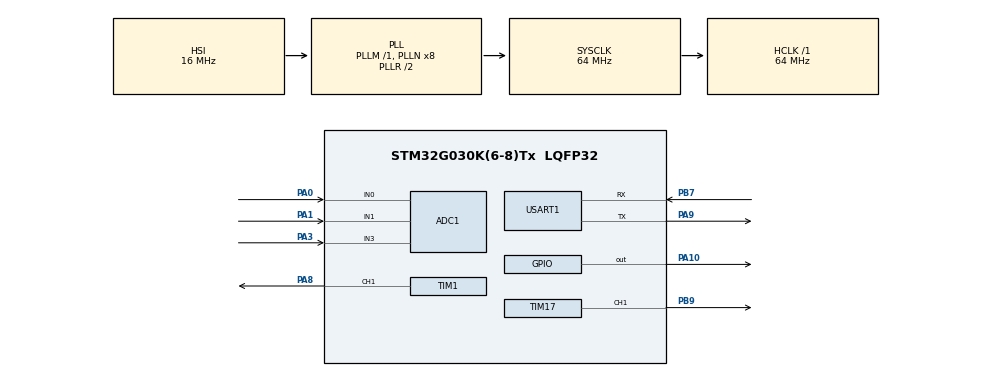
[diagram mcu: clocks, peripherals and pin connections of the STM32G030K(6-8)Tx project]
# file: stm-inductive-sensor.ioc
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ADC1.Channel-0\#ChannelRegularConversion=ADC_CHANNEL_1
ADC1.Channel-1\#ChannelRegularConversion=ADC_CHANNEL_3
ADC1.ClockPrescaler=ADC_CLOCK_ASYNC_DIV1
ADC1.ContinuousConvMode=ENABLE
ADC1.DMAContinuousRequests=DISABLE
ADC1.EOCSelection=ADC_EOC_SEQ_CONV
ADC1.ExternalTrigConv=ADC_SOFTWARE_START
ADC1.NbrOfConversion=2
ADC1.NbrOfConversionFlag=1
ADC1.Overrun=ADC_OVR_DATA_PRESERVED
ADC1.OversamplingMode=DISABLE
ADC1.Rank-0\#ChannelRegularConversion=1
ADC1.Rank-1\#ChannelRegularConversion=2
ADC1.SamplingTime-0\#ChannelRegularConversion=ADC_SAMPLINGTIME_COMMON_1
ADC1.SamplingTime-1\#ChannelRegularConversion=ADC_SAMPLINGTIME_COMMON_1
ADC1.SamplingTimeCommon1=ADC_SAMPLETIME_19CYCLES_5
ADC1.SamplingTimeCommon2=ADC_SAMPLETIME_39CYCLES_5
ADC1.SelectedChannel=ADC_CHANNEL_0|ADC_CHANNEL_1|ADC_CHANNEL_3
ADC1.Sequencer=FULLY_CONFIGURABLE
ADC1.TriggerFrequencyMode=ADC_TRIGGER_FREQ_HIGH
ADC1.master=1
Dma.ADC1.0.Direction=DMA_PERIPH_TO_MEMORY
Dma.ADC1.0.EventEnable=DISABLE
Dma.ADC1.0.Instance=DMA1_Channel1
Dma.ADC1.0.MemDataAlignment=DMA_MDATAALIGN_HALFWORD
Dma.ADC1.0.MemInc=DMA_MINC_ENABLE
Dma.ADC1.0.Mode=DMA_NORMAL
Dma.ADC1.0.PeriphDataAlignment=DMA_PDATAALIGN_HALFWORD
Dma.ADC1.0.PeriphInc=DMA_PINC_DISABLE
Dma.ADC1.0.Polarity=HAL_DMAMUX_REQ_GEN_RISING
Dma.ADC1.0.Priority=DMA_PRIORITY_LOW
Dma.ADC1.0.RequestNumber=1
Dma.ADC1.0.SignalID=NONE
Dma.ADC1.0.SyncEnable=DISABLE
Dma.ADC1.0.SyncPolarity=HAL_DMAMUX_SYNC_NO_EVENT
Dma.ADC1.0.SyncRequestNumber=1
Dma.ADC1.0.SyncSignalID=NONE
Dma.Request0=ADC1
Dma.Request1=USART1_TX
Dma.USART1_TX.1.Direction=DMA_MEMORY_TO_PERIPH
Dma.USART1_TX.1.EventEnable=DISABLE
Dma.USART1_TX.1.Instance=DMA1_Channel2
Dma.USART1_TX.1.MemDataAlignment=DMA_MDATAALIGN_BYTE
Dma.USART1_TX.1.MemInc=DMA_MINC_ENABLE
Dma.USART1_TX.1.Mode=DMA_NORMAL
Dma.USART1_TX.1.PeriphDataAlignment=DMA_PDATAALIGN_BYTE
Dma.USART1_TX.1.PeriphInc=DMA_PINC_DISABLE
Dma.USART1_TX.1.Polarity=HAL_DMAMUX_REQ_GEN_RISING
Dma.USART1_TX.1.Priority=DMA_PRIORITY_LOW
Dma.USART1_TX.1.RequestNumber=1
Dma.USART1_TX.1.SignalID=NONE
Dma.USART1_TX.1.SyncEnable=DISABLE
Dma.USART1_TX.1.SyncPolarity=HAL_DMAMUX_SYNC_NO_EVENT
Dma.USART1_TX.1.SyncRequestNumber=1
Dma.USART1_TX.1.SyncSignalID=NONE
Mcu.Family=STM32G0
Mcu.Name=STM32G030K(6-8)Tx
Mcu.Package=LQFP32
NVIC.DMA1_Channel1_IRQn=true\:0\:0\:false\:false\:true\:false\:true\:true
NVIC.DMA1_Channel2_3_IRQn=true\:0\:0\:false\:false\:true\:false\:true\:true
NVIC.TIM1_BRK_UP_TRG_COM_IRQn=true\:0\:0\:false\:false\:true\:true\:true\:true
NVIC.USART1_IRQn=true\:0\:0\:false\:false\:true\:true\:true\:true
PA0.Mode=IN0
PA0.Signal=ADC1_IN0
PA1.Mode=IN1
PA1.Signal=ADC1_IN1
PA10.Signal=GPIO_Output
PA13.Mode=Serial_Wire
PA13.Signal=SYS_SWDIO
PA14-BOOT0.Mode=Serial_Wire
PA14-BOOT0.Signal=SYS_SWCLK
PA3.Mode=IN3
PA3.Signal=ADC1_IN3
PA8.Signal=S_TIM1_CH1
PA9.Mode=Asynchronous
PA9.Signal=USART1_TX
PB7.Mode=Asynchronous
PB7.Signal=USART1_RX
PB9.Signal=S_TIM17_CH1
ProjectManager.HeapSize=0x200
ProjectManager.StackSize=0x400
ProjectManager.TargetToolchain=STM32CubeIDE
RCC.ADCFreq_Value=64000000
RCC.AHBFreq_Value=64000000
RCC.CortexFreq_Value=64000000
RCC.EXTERNAL_CLOCK_VALUE=12288000
RCC.HCLKFreq_Value=64000000
RCC.HSE_VALUE=8000000
RCC.HSI_VALUE=16000000
RCC.LSE_VALUE=32768
RCC.SYSCLKFreq_VALUE=64000000
RCC.SYSCLKSource=RCC_SYSCLKSOURCE_PLLCLK
RCC.VCOOutputFreq_Value=128000000
SH.S_TIM17_CH1.0=TIM17_CH1,PWM Generation1 CH1
SH.S_TIM1_CH1.0=TIM1_CH1,PWM Generation1 CH1
TIM1.Channel-PWM\ Generation1\ CH1=TIM_CHANNEL_1
TIM1.Period=50000-1
TIM1.Prescaler=64-1
TIM17.Channel=TIM_CHANNEL_1
TIM17.Period=639
TIM17.Pulse=319
USART1.VirtualMode-Asynchronous=VM_ASYNC
VP_TIM17_VS_ClockSourceINT.Mode=Enable_Timer
VP_TIM1_VS_ClockSourceINT.Mode=Internal
board=custom

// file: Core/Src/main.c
/* USER CODE BEGIN Header */
/**
  ******************************************************************************
  * @file           : main.c
  * @brief          : Main program body
  ******************************************************************************
  * @attention
  *
  * Copyright (c) 2023 STMicroelectronics.
  * All rights reserved.
  *
  * This software is licensed under terms that can be found in the LICENSE file
  * in the root directory of this software component.
  * If no LICENSE file comes with this software, it is provided AS-IS.
  *
  ******************************************************************************
  */
/* USER CODE END Header */
#include "main.h"

/* USER CODE BEGIN Includes */
#include "application.h"
/* USER CODE END Includes */

ADC_HandleTypeDef hadc1;
DMA_HandleTypeDef hdma_adc1;

TIM_HandleTypeDef htim1;
TIM_HandleTypeDef htim17;

UART_HandleTypeDef huart1;
DMA_HandleTypeDef hdma_usart1_tx;

void SystemClock_Config(void);
static void MX_GPIO_Init(void);
static void MX_DMA_Init(void);
static void MX_ADC1_Init(void);
static void MX_TIM17_Init(void);
static void MX_TIM1_Init(void);
static void MX_USART1_UART_Init(void);

int main(void)
{

  /* MCU Configuration--------------------------------------------------------*/

  /* Reset of all peripherals, Initializes the Flash interface and the Systick. */
  HAL_Init();

  /* Configure the system clock */
  SystemClock_Config();

  /* Initialize all configured peripherals */
  MX_GPIO_Init();
  MX_DMA_Init();
  MX_ADC1_Init();
  MX_TIM17_Init();
  MX_TIM1_Init();
  MX_USART1_UART_Init();

  /* Infinite loop */
  /* USER CODE BEGIN WHILE */
  application_init();
  while (1)
  {
	  appliation_loop();
    /* USER CODE END WHILE */

  }
}

void SystemClock_Config(void)
{
  RCC_OscInitTypeDef RCC_OscInitStruct = {0};
  RCC_ClkInitTypeDef RCC_ClkInitStruct = {0};

  /** Configure the main internal regulator output voltage
  */
  HAL_PWREx_ControlVoltageScaling(PWR_REGULATOR_VOLTAGE_SCALE1);

  /** Initializes the RCC Oscillators according to the specified parameters
  * in the RCC_OscInitTypeDef structure.
  */
  RCC_OscInitStruct.OscillatorType = RCC_OSCILLATORTYPE_HSI;
  RCC_OscInitStruct.HSIState = RCC_HSI_ON;
  RCC_OscInitStruct.HSIDiv = RCC_HSI_DIV1;
  RCC_OscInitStruct.HSICalibrationValue = RCC_HSICALIBRATION_DEFAULT;
  RCC_OscInitStruct.PLL.PLLState = RCC_PLL_ON;
  RCC_OscInitStruct.PLL.PLLSource = RCC_PLLSOURCE_HSI;
  RCC_OscInitStruct.PLL.PLLM = RCC_PLLM_DIV1;
  RCC_OscInitStruct.PLL.PLLN = 8;
  RCC_OscInitStruct.PLL.PLLP = RCC_PLLP_DIV2;
  RCC_OscInitStruct.PLL.PLLR = RCC_PLLR_DIV2;
  if (HAL_RCC_OscConfig(&RCC_OscInitStruct) != HAL_OK)
  {
    Error_Handler();
  }

  /** Initializes the CPU, AHB and APB buses clocks
  */
  RCC_ClkInitStruct.ClockType = RCC_CLOCKTYPE_HCLK|RCC_CLOCKTYPE_SYSCLK
                              |RCC_CLOCKTYPE_PCLK1;
  RCC_ClkInitStruct.SYSCLKSource = RCC_SYSCLKSOURCE_PLLCLK;
  RCC_ClkInitStruct.AHBCLKDivider = RCC_SYSCLK_DIV1;
  RCC_ClkInitStruct.APB1CLKDivider = RCC_HCLK_DIV1;

  if (HAL_RCC_ClockConfig(&RCC_ClkInitStruct, FLASH_LATENCY_2) != HAL_OK)
  {
    Error_Handler();
  }
}

static void MX_ADC1_Init(void)
{

  ADC_ChannelConfTypeDef sConfig = {0};

  /** Configure the global features of the ADC (Clock, Resolution, Data Alignment and number of conversion)
  */
  hadc1.Instance = ADC1;
  hadc1.Init.ClockPrescaler = ADC_CLOCK_ASYNC_DIV1;
  hadc1.Init.Resolution = ADC_RESOLUTION_12B;
  hadc1.Init.DataAlign = ADC_DATAALIGN_RIGHT;
  hadc1.Init.ScanConvMode = ADC_SCAN_ENABLE;
  hadc1.Init.EOCSelection = ADC_EOC_SEQ_CONV;
  hadc1.Init.LowPowerAutoWait = DISABLE;
  hadc1.Init.LowPowerAutoPowerOff = DISABLE;
  hadc1.Init.ContinuousConvMode = ENABLE;
  hadc1.Init.NbrOfConversion = 2;
  hadc1.Init.ExternalTrigConv = ADC_SOFTWARE_START;
  hadc1.Init.ExternalTrigConvEdge = ADC_EXTERNALTRIGCONVEDGE_NONE;
  hadc1.Init.DMAContinuousRequests = DISABLE;
  hadc1.Init.Overrun = ADC_OVR_DATA_PRESERVED;
  hadc1.Init.SamplingTimeCommon1 = ADC_SAMPLETIME_19CYCLES_5;
  hadc1.Init.SamplingTimeCommon2 = ADC_SAMPLETIME_39CYCLES_5;
  hadc1.Init.OversamplingMode = DISABLE;
  hadc1.Init.TriggerFrequencyMode = ADC_TRIGGER_FREQ_HIGH;
  if (HAL_ADC_Init(&hadc1) != HAL_OK)
  {
    Error_Handler();
  }

  /** Configure Regular Channel
  */
  sConfig.Channel = ADC_CHANNEL_1;
  sConfig.Rank = ADC_REGULAR_RANK_1;
  sConfig.SamplingTime = ADC_SAMPLINGTIME_COMMON_1;
  if (HAL_ADC_ConfigChannel(&hadc1, &sConfig) != HAL_OK)
  {
    Error_Handler();
  }

  /** Configure Regular Channel
  */
  sConfig.Channel = ADC_CHANNEL_3;
  sConfig.Rank = ADC_REGULAR_RANK_2;
  if (HAL_ADC_ConfigChannel(&hadc1, &sConfig) != HAL_OK)
  {
    Error_Handler();
  }

}

static void MX_TIM1_Init(void)
{

  TIM_ClockConfigTypeDef sClockSourceConfig = {0};
  TIM_MasterConfigTypeDef sMasterConfig = {0};
  TIM_OC_InitTypeDef sConfigOC = {0};
  TIM_BreakDeadTimeConfigTypeDef sBreakDeadTimeConfig = {0};

  htim1.Instance = TIM1;
  htim1.Init.Prescaler = 64-1;
  htim1.Init.CounterMode = TIM_COUNTERMODE_UP;
  htim1.Init.Period = 50000-1;
  htim1.Init.ClockDivision = TIM_CLOCKDIVISION_DIV1;
  htim1.Init.RepetitionCounter = 0;
  htim1.Init.AutoReloadPreload = TIM_AUTORELOAD_PRELOAD_DISABLE;
  if (HAL_TIM_Base_Init(&htim1) != HAL_OK)
  {
    Error_Handler();
  }
  sClockSourceConfig.ClockSource = TIM_CLOCKSOURCE_INTERNAL;
  if (HAL_TIM_ConfigClockSource(&htim1, &sClockSourceConfig) != HAL_OK)
  {
    Error_Handler();
  }
  if (HAL_TIM_PWM_Init(&htim1) != HAL_OK)
  {
    Error_Handler();
  }
  sMasterConfig.MasterOutputTrigger = TIM_TRGO_RESET;
  sMasterConfig.MasterOutputTrigger2 = TIM_TRGO2_RESET;
  sMasterConfig.MasterSlaveMode = TIM_MASTERSLAVEMODE_DISABLE;
  if (HAL_TIMEx_MasterConfigSynchronization(&htim1, &sMasterConfig) != HAL_OK)
  {
    Error_Handler();
  }
  sConfigOC.OCMode = TIM_OCMODE_PWM1;
  sConfigOC.Pulse = 0;
  sConfigOC.OCPolarity = TIM_OCPOLARITY_HIGH;
  sConfigOC.OCNPolarity = TIM_OCNPOLARITY_HIGH;
  sConfigOC.OCFastMode = TIM_OCFAST_DISABLE;
  sConfigOC.OCIdleState = TIM_OCIDLESTATE_RESET;
  sConfigOC.OCNIdleState = TIM_OCNIDLESTATE_RESET;
  if (HAL_TIM_PWM_ConfigChannel(&htim1, &sConfigOC, TIM_CHANNEL_1) != HAL_OK)
  {
    Error_Handler();
  }
  sBreakDeadTimeConfig.OffStateRunMode = TIM_OSSR_DISABLE;
  sBreakDeadTimeConfig.OffStateIDLEMode = TIM_OSSI_DISABLE;
  sBreakDeadTimeConfig.LockLevel = TIM_LOCKLEVEL_OFF;
  sBreakDeadTimeConfig.DeadTime = 0;
  sBreakDeadTimeConfig.BreakState = TIM_BREAK_DISABLE;
  sBreakDeadTimeConfig.BreakPolarity = TIM_BREAKPOLARITY_HIGH;
  sBreakDeadTimeConfig.BreakFilter = 0;
  sBreakDeadTimeConfig.BreakAFMode = TIM_BREAK_AFMODE_INPUT;
  sBreakDeadTimeConfig.Break2State = TIM_BREAK2_DISABLE;
  sBreakDeadTimeConfig.Break2Polarity = TIM_BREAK2POLARITY_HIGH;
  sBreakDeadTimeConfig.Break2Filter = 0;
  sBreakDeadTimeConfig.Break2AFMode = TIM_BREAK_AFMODE_INPUT;
  sBreakDeadTimeConfig.AutomaticOutput = TIM_AUTOMATICOUTPUT_DISABLE;
  if (HAL_TIMEx_ConfigBreakDeadTime(&htim1, &sBreakDeadTimeConfig) != HAL_OK)
  {
    Error_Handler();
  }
  HAL_TIM_MspPostInit(&htim1);

}

static void MX_TIM17_Init(void)
{

  TIM_OC_InitTypeDef sConfigOC = {0};
  TIM_BreakDeadTimeConfigTypeDef sBreakDeadTimeConfig = {0};

  htim17.Instance = TIM17;
  htim17.Init.Prescaler = 0;
  htim17.Init.CounterMode = TIM_COUNTERMODE_UP;
  htim17.Init.Period = 639;
  htim17.Init.ClockDivision = TIM_CLOCKDIVISION_DIV1;
  htim17.Init.RepetitionCounter = 0;
  htim17.Init.AutoReloadPreload = TIM_AUTORELOAD_PRELOAD_DISABLE;
  if (HAL_TIM_Base_Init(&htim17) != HAL_OK)
  {
    Error_Handler();
  }
  if (HAL_TIM_PWM_Init(&htim17) != HAL_OK)
  {
    Error_Handler();
  }
  sConfigOC.OCMode = TIM_OCMODE_PWM1;
  sConfigOC.Pulse = 319;
  sConfigOC.OCPolarity = TIM_OCPOLARITY_HIGH;
  sConfigOC.OCNPolarity = TIM_OCNPOLARITY_HIGH;
  sConfigOC.OCFastMode = TIM_OCFAST_DISABLE;
  sConfigOC.OCIdleState = TIM_OCIDLESTATE_RESET;
  sConfigOC.OCNIdleState = TIM_OCNIDLESTATE_RESET;
  if (HAL_TIM_PWM_ConfigChannel(&htim17, &sConfigOC, TIM_CHANNEL_1) != HAL_OK)
  {
    Error_Handler();
  }
  sBreakDeadTimeConfig.OffStateRunMode = TIM_OSSR_DISABLE;
  sBreakDeadTimeConfig.OffStateIDLEMode = TIM_OSSI_DISABLE;
  sBreakDeadTimeConfig.LockLevel = TIM_LOCKLEVEL_OFF;
  sBreakDeadTimeConfig.DeadTime = 0;
  sBreakDeadTimeConfig.BreakState = TIM_BREAK_DISABLE;
  sBreakDeadTimeConfig.BreakPolarity = TIM_BREAKPOLARITY_HIGH;
  sBreakDeadTimeConfig.BreakFilter = 0;
  sBreakDeadTimeConfig.AutomaticOutput = TIM_AUTOMATICOUTPUT_DISABLE;
  if (HAL_TIMEx_ConfigBreakDeadTime(&htim17, &sBreakDeadTimeConfig) != HAL_OK)
  {
    Error_Handler();
  }
  HAL_TIM_MspPostInit(&htim17);

}

static void MX_USART1_UART_Init(void)
{

  huart1.Instance = USART1;
  huart1.Init.BaudRate = 115200;
  huart1.Init.WordLength = UART_WORDLENGTH_8B;
  huart1.Init.StopBits = UART_STOPBITS_1;
  huart1.Init.Parity = UART_PARITY_NONE;
  huart1.Init.Mode = UART_MODE_TX_RX;
  huart1.Init.HwFlowCtl = UART_HWCONTROL_NONE;
  huart1.Init.OverSampling = UART_OVERSAMPLING_16;
  huart1.Init.OneBitSampling = UART_ONE_BIT_SAMPLE_DISABLE;
  huart1.Init.ClockPrescaler = UART_PRESCALER_DIV1;
  huart1.AdvancedInit.AdvFeatureInit = UART_ADVFEATURE_NO_INIT;
  if (HAL_UART_Init(&huart1) != HAL_OK)
  {
    Error_Handler();
  }
  if (HAL_UARTEx_SetTxFifoThreshold(&huart1, UART_TXFIFO_THRESHOLD_1_8) != HAL_OK)
  {
    Error_Handler();
  }
  if (HAL_UARTEx_SetRxFifoThreshold(&huart1, UART_RXFIFO_THRESHOLD_1_8) != HAL_OK)
  {
    Error_Handler();
  }
  if (HAL_UARTEx_DisableFifoMode(&huart1) != HAL_OK)
  {
    Error_Handler();
  }

}

static void MX_DMA_Init(void)
{

  /* DMA controller clock enable */
  __HAL_RCC_DMA1_CLK_ENABLE();

  /* DMA interrupt init */
  /* DMA1_Channel1_IRQn interrupt configuration */
  HAL_NVIC_SetPriority(DMA1_Channel1_IRQn, 0, 0);
  HAL_NVIC_EnableIRQ(DMA1_Channel1_IRQn);
  /* DMA1_Channel2_3_IRQn interrupt configuration */
  HAL_NVIC_SetPriority(DMA1_Channel2_3_IRQn, 0, 0);
  HAL_NVIC_EnableIRQ(DMA1_Channel2_3_IRQn);

}

static void MX_GPIO_Init(void)
{
  GPIO_InitTypeDef GPIO_InitStruct = {0};

  /* GPIO Ports Clock Enable */
  __HAL_RCC_GPIOB_CLK_ENABLE();
  __HAL_RCC_GPIOA_CLK_ENABLE();

  /*Configure GPIO pin Output Level */
  HAL_GPIO_WritePin(GPIOA, GPIO_PIN_10, GPIO_PIN_RESET);

  /*Configure GPIO pin : PA10 */
  GPIO_InitStruct.Pin = GPIO_PIN_10;
  GPIO_InitStruct.Mode = GPIO_MODE_OUTPUT_PP;
  GPIO_InitStruct.Pull = GPIO_NOPULL;
  GPIO_InitStruct.Speed = GPIO_SPEED_FREQ_LOW;
  HAL_GPIO_Init(GPIOA, &GPIO_InitStruct);

}

void Error_Handler(void)
{
  __disable_irq();
  while (1)
  {
  }
}
